VERSION ""

NS_ :

BS_:

BU_: XXX

BO_ 239 NEW_MSG_1: 8 XXX
 SG_ NEW_SIGNAL_1 : 7|8@0+ (1,0) [0|255] "" XXX
 SG_ NEW_SIGNAL_2 : 15|8@0+ (1,0) [0|255] "" XXX

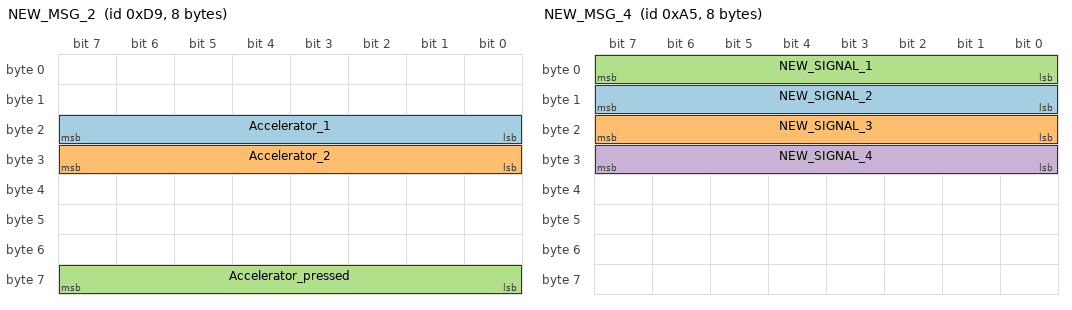
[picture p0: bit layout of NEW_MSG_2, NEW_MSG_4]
BO_ 217 NEW_MSG_2: 8 XXX
 SG_ Accelerator_1 : 23|8@0+ (1,0) [0|255] "" XXX
 SG_ Accelerator_2 : 31|8@0+ (1,0) [0|255] "" XXX
 SG_ Accelerator_pressed : 63|8@0+ (1,0) [0|255] "" XXX

BO_ 274 NEW_MSG_3: 8 XXX
 SG_ NEW_SIGNAL_1 : 23|8@0+ (1,0) [0|255] "" XXX

BO_ 165 NEW_MSG_4: 8 XXX
 SG_ NEW_SIGNAL_2 : 15|8@0+ (1,0) [0|255] "" XXX
 SG_ NEW_SIGNAL_3 : 23|8@0+ (1,0) [0|255] "" XXX
 SG_ NEW_SIGNAL_1 : 7|8@0+ (1,0) [0|255] "" XXX
 SG_ NEW_SIGNAL_4 : 31|8@0+ (1,0) [0|255] "" XXX

BO_ 243 NEW_MSG_5: 8 XXX
 SG_ NEW_SIGNAL_1 : 7|8@0+ (1,0) [0|255] "" XXX
 SG_ NEW_SIGNAL_2 : 15|8@0+ (1,0) [0|255] "" XXX

BO_ 409 NEW_MSG_6: 8 XXX
 SG_ NEW_SIGNAL_1 : 23|8@0+ (1,0) [0|255] "" XXX

BO_ 410 NEW_MSG_7: 8 XXX
 SG_ NEW_SIGNAL_1 : 23|8@0+ (1,0) [0|255] "" XXX

BO_ 415 NEW_MSG_8: 8 XXX
 SG_ NEW_SIGNAL_1 : 23|8@0+ (1,0) [0|255] "" XXX

BO_ 596 NEW_MSG_9: 8 XXX
 SG_ NEW_SIGNAL_1 : 7|8@0+ (1,0) [0|255] "" XXX
